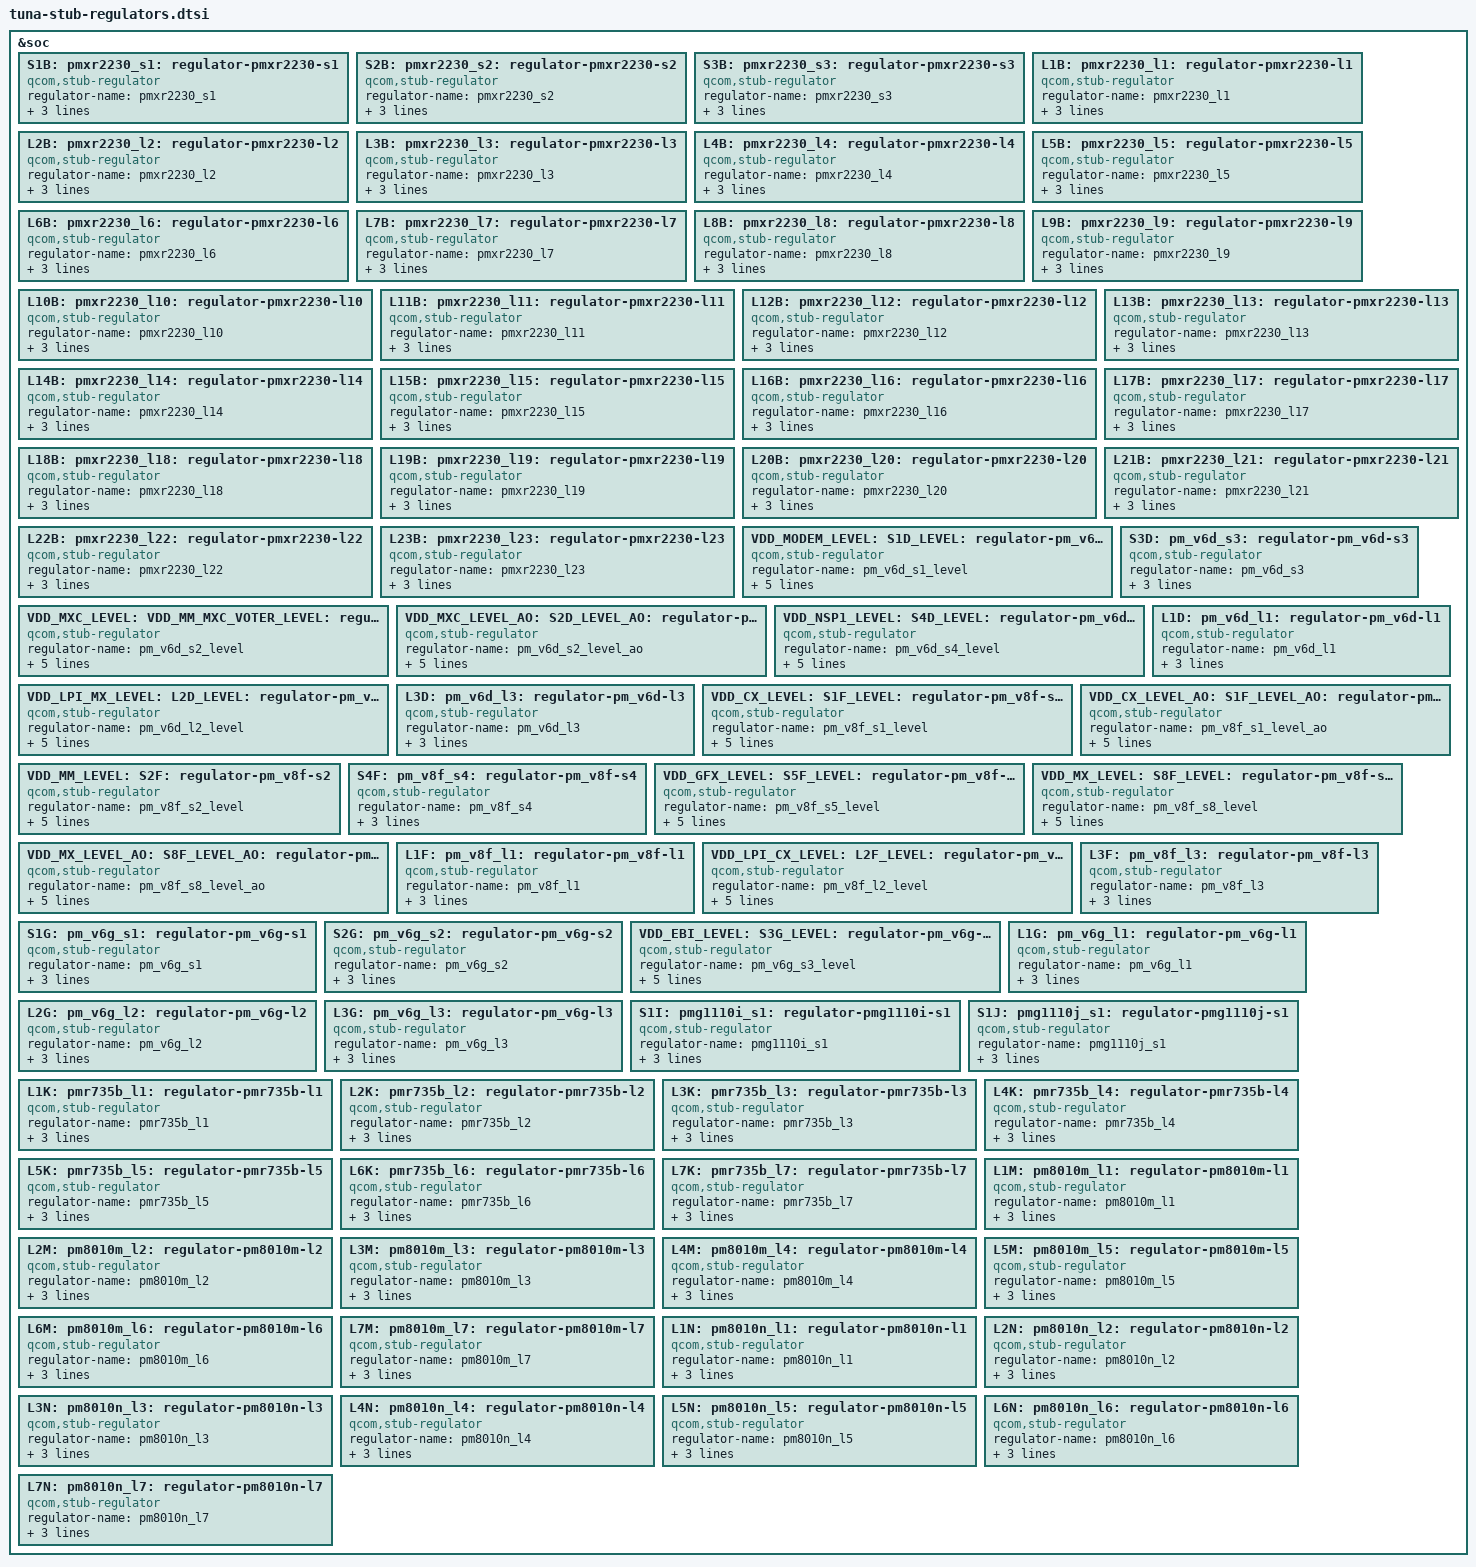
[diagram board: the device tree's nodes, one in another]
// SPDX-License-Identifier: BSD-3-Clause
/*
 * Copyright (c) 2023-2024 Qualcomm Innovation Center, Inc. All rights reserved.
 */

#include <dt-bindings/regulator/qcom,rpmh-regulator-levels.h>

&soc {

		S1B:
		pmxr2230_s1: regulator-pmxr2230-s1 {
			compatible = "qcom,stub-regulator";
			regulator-name = "pmxr2230_s1";
			qcom,hpm-min-load = <10000>;
			regulator-min-microvolt = <1850000>;
			regulator-max-microvolt = <2100000>;
		};

		S2B:
		pmxr2230_s2: regulator-pmxr2230-s2 {
			compatible = "qcom,stub-regulator";
			regulator-name = "pmxr2230_s2";
			qcom,hpm-min-load = <10000>;
			regulator-min-microvolt = <1250000>;
			regulator-max-microvolt = <2100000>;
		};

		S3B:
		pmxr2230_s3: regulator-pmxr2230-s3 {
			compatible = "qcom,stub-regulator";
			regulator-name = "pmxr2230_s3";
			qcom,hpm-min-load = <10000>;
			regulator-min-microvolt = <690000>;
			regulator-max-microvolt = <2100000>;
		};

		L1B:
		pmxr2230_l1: regulator-pmxr2230-l1 {
			compatible = "qcom,stub-regulator";
			regulator-name = "pmxr2230_l1";
			qcom,hpm-min-load = <10000>;
			regulator-min-microvolt = <866000>;
			regulator-max-microvolt = <958000>;
		};

		L2B:
		pmxr2230_l2: regulator-pmxr2230-l2 {
			compatible = "qcom,stub-regulator";
			regulator-name = "pmxr2230_l2";
			qcom,hpm-min-load = <10000>;
			regulator-min-microvolt = <720000>;
			regulator-max-microvolt = <950000>;
		};

		L3B:
		pmxr2230_l3: regulator-pmxr2230-l3 {
			compatible = "qcom,stub-regulator";
			regulator-name = "pmxr2230_l3";
			qcom,hpm-min-load = <10000>;
			regulator-min-microvolt = <831000>;
			regulator-max-microvolt = <919000>;
		};

		L4B:
		pmxr2230_l4: regulator-pmxr2230-l4 {
			compatible = "qcom,stub-regulator";
			regulator-name = "pmxr2230_l4";
			qcom,hpm-min-load = <10000>;
			regulator-min-microvolt = <1080000>;
			regulator-max-microvolt = <1320000>;
		};

		L5B:
		pmxr2230_l5: regulator-pmxr2230-l5 {
			compatible = "qcom,stub-regulator";
			regulator-name = "pmxr2230_l5";
			qcom,hpm-min-load = <10000>;
			regulator-min-microvolt = <1000000>;
			regulator-max-microvolt = <1980000>;
		};

		L6B:
		pmxr2230_l6: regulator-pmxr2230-l6 {
			compatible = "qcom,stub-regulator";
			regulator-name = "pmxr2230_l6";
			qcom,hpm-min-load = <10000>;
			regulator-min-microvolt = <1170000>;
			regulator-max-microvolt = <1370000>;
		};

		L7B:
		pmxr2230_l7: regulator-pmxr2230-l7 {
			compatible = "qcom,stub-regulator";
			regulator-name = "pmxr2230_l7";
			qcom,hpm-min-load = <10000>;
			regulator-min-microvolt = <1080000>;
			regulator-max-microvolt = <1980000>;
		};

		L8B:
		pmxr2230_l8: regulator-pmxr2230-l8 {
			compatible = "qcom,stub-regulator";
			regulator-name = "pmxr2230_l8";
			qcom,hpm-min-load = <10000>;
			regulator-min-microvolt = <1650000>;
			regulator-max-microvolt = <1950000>;
		};

		L9B:
		pmxr2230_l9: regulator-pmxr2230-l9 {
			compatible = "qcom,stub-regulator";
			regulator-name = "pmxr2230_l9";
			qcom,hpm-min-load = <10000>;
			regulator-min-microvolt = <756000>;
			regulator-max-microvolt = <816000>;
		};

		L10B:
		pmxr2230_l10: regulator-pmxr2230-l10 {
			compatible = "qcom,stub-regulator";
			regulator-name = "pmxr2230_l10";
			qcom,hpm-min-load = <10000>;
			regulator-min-microvolt = <866000>;
			regulator-max-microvolt = <931000>;
		};

		L11B:
		pmxr2230_l11: regulator-pmxr2230-l11 {
			compatible = "qcom,stub-regulator";
			regulator-name = "pmxr2230_l11";
			qcom,hpm-min-load = <10000>;
			regulator-min-microvolt = <1620000>;
			regulator-max-microvolt = <2000000>;
		};

		L12B:
		pmxr2230_l12: regulator-pmxr2230-l12 {
			compatible = "qcom,stub-regulator";
			regulator-name = "pmxr2230_l12";
			qcom,hpm-min-load = <10000>;
			regulator-min-microvolt = <2400000>;
			regulator-max-microvolt = <3300000>;
		};

		L13B:
		pmxr2230_l13: regulator-pmxr2230-l13 {
			compatible = "qcom,stub-regulator";
			regulator-name = "pmxr2230_l13";
			qcom,hpm-min-load = <10000>;
			regulator-min-microvolt = <2700000>;
			regulator-max-microvolt = <3300000>;
		};

		L14B:
		pmxr2230_l14: regulator-pmxr2230-l14 {
			compatible = "qcom,stub-regulator";
			regulator-name = "pmxr2230_l14";
			qcom,hpm-min-load = <10000>;
			regulator-min-microvolt = <1504000>;
			regulator-max-microvolt = <3544000>;
		};

		L15B:
		pmxr2230_l15: regulator-pmxr2230-l15 {
			compatible = "qcom,stub-regulator";
			regulator-name = "pmxr2230_l15";
			qcom,hpm-min-load = <10000>;
			regulator-min-microvolt = <1620000>;
			regulator-max-microvolt = <3300000>;
		};

		L16B:
		pmxr2230_l16: regulator-pmxr2230-l16 {
			compatible = "qcom,stub-regulator";
			regulator-name = "pmxr2230_l16";
			qcom,hpm-min-load = <10000>;
			regulator-min-microvolt = <2900000>;
			regulator-max-microvolt = <3544000>;
		};

		L17B:
		pmxr2230_l17: regulator-pmxr2230-l17 {
			compatible = "qcom,stub-regulator";
			regulator-name = "pmxr2230_l17";
			qcom,hpm-min-load = <10000>;
			regulator-min-microvolt = <2700000>;
			regulator-max-microvolt = <3544000>;
		};

		L18B:
		pmxr2230_l18: regulator-pmxr2230-l18 {
			compatible = "qcom,stub-regulator";
			regulator-name = "pmxr2230_l18";
			qcom,hpm-min-load = <10000>;
			regulator-min-microvolt = <1600000>;
			regulator-max-microvolt = <3544000>;
		};

		L19B:
		pmxr2230_l19: regulator-pmxr2230-l19 {
			compatible = "qcom,stub-regulator";
			regulator-name = "pmxr2230_l19";
			qcom,hpm-min-load = <10000>;
			regulator-min-microvolt = <2600000>;
			regulator-max-microvolt = <3544000>;
		};

		L20B:
		pmxr2230_l20: regulator-pmxr2230-l20 {
			compatible = "qcom,stub-regulator";
			regulator-name = "pmxr2230_l20";
			qcom,hpm-min-load = <10000>;
			regulator-min-microvolt = <1504000>;
			regulator-max-microvolt = <3544000>;
		};

		L21B:
		pmxr2230_l21: regulator-pmxr2230-l21 {
			compatible = "qcom,stub-regulator";
			regulator-name = "pmxr2230_l21";
			qcom,hpm-min-load = <10000>;
			regulator-min-microvolt = <1504000>;
			regulator-max-microvolt = <3544000>;
		};

		L22B:
		pmxr2230_l22: regulator-pmxr2230-l22 {
			compatible = "qcom,stub-regulator";
			regulator-name = "pmxr2230_l22";
			qcom,hpm-min-load = <10000>;
			regulator-min-microvolt = <2700000>;
			regulator-max-microvolt = <3400000>;
		};

		L23B:
		pmxr2230_l23: regulator-pmxr2230-l23 {
			compatible = "qcom,stub-regulator";
			regulator-name = "pmxr2230_l23";
			qcom,hpm-min-load = <10000>;
			regulator-min-microvolt = <1650000>;
			regulator-max-microvolt = <3544000>;
		};

		VDD_MODEM_LEVEL:
		S1D_LEVEL:
		pm_v6d_s1_level: regulator-pm_v6d-s1-level {
			compatible = "qcom,stub-regulator";
			regulator-name = "pm_v6d_s1_level";
			qcom,hpm-min-load = <10000>;
			regulator-min-microvolt =
				<RPMH_REGULATOR_LEVEL_RETENTION>;
			regulator-max-microvolt = <RPMH_REGULATOR_LEVEL_MAX>;
		};

		VDD_MXC_LEVEL:
		VDD_MM_MXC_VOTER_LEVEL:
		VDD_GFX_MXC_VOTER_LEVEL:
		S2D_LEVEL:
		pm_v6d_s2_level: regulator-pm_v6d-s2-level {
			compatible = "qcom,stub-regulator";
			regulator-name = "pm_v6d_s2_level";
			qcom,hpm-min-load = <10000>;
			regulator-min-microvolt =
				<RPMH_REGULATOR_LEVEL_RETENTION>;
			regulator-max-microvolt = <RPMH_REGULATOR_LEVEL_MAX>;
		};

		VDD_MXC_LEVEL_AO:
		S2D_LEVEL_AO:
		pm_v6d_s2_level_ao: regulator-pm_v6d-s2-level-ao {
			compatible = "qcom,stub-regulator";
			regulator-name = "pm_v6d_s2_level_ao";
			qcom,hpm-min-load = <10000>;
			regulator-min-microvolt =
				<RPMH_REGULATOR_LEVEL_RETENTION>;
			regulator-max-microvolt = <RPMH_REGULATOR_LEVEL_MAX>;
		};

		S3D:
		pm_v6d_s3: regulator-pm_v6d-s3 {
			compatible = "qcom,stub-regulator";
			regulator-name = "pm_v6d_s3";
			qcom,hpm-min-load = <10000>;
			regulator-min-microvolt = <870000>;
			regulator-max-microvolt = <970000>;
		};

		VDD_NSP1_LEVEL:
		S4D_LEVEL:
		pm_v6d_s4_level: regulator-pm_v6d-s4-level {
			compatible = "qcom,stub-regulator";
			regulator-name = "pm_v6d_s4_level";
			qcom,hpm-min-load = <10000>;
			regulator-min-microvolt =
				<RPMH_REGULATOR_LEVEL_RETENTION>;
			regulator-max-microvolt = <RPMH_REGULATOR_LEVEL_MAX>;
		};

		L1D:
		pm_v6d_l1: regulator-pm_v6d-l1 {
			compatible = "qcom,stub-regulator";
			regulator-name = "pm_v6d_l1";
			qcom,hpm-min-load = <10000>;
			regulator-min-microvolt = <320000>;
			regulator-max-microvolt = <2000000>;
		};

		VDD_LPI_MX_LEVEL:
		L2D_LEVEL:
		pm_v6d_l2_level: regulator-pm_v6d-l2-level {
			compatible = "qcom,stub-regulator";
			regulator-name = "pm_v6d_l2_level";
			qcom,hpm-min-load = <10000>;
			regulator-min-microvolt =
				<RPMH_REGULATOR_LEVEL_RETENTION>;
			regulator-max-microvolt = <RPMH_REGULATOR_LEVEL_MAX>;
		};

		L3D:
		pm_v6d_l3: regulator-pm_v6d-l3 {
			compatible = "qcom,stub-regulator";
			regulator-name = "pm_v6d_l3";
			qcom,hpm-min-load = <10000>;
			regulator-min-microvolt = <1030000>;
			regulator-max-microvolt = <1350000>;
		};

		VDD_CX_LEVEL:
		S1F_LEVEL:
		pm_v8f_s1_level: regulator-pm_v8f-s1-level {
			compatible = "qcom,stub-regulator";
			regulator-name = "pm_v8f_s1_level";
			qcom,hpm-min-load = <10000>;
			regulator-min-microvolt =
				<RPMH_REGULATOR_LEVEL_RETENTION>;
			regulator-max-microvolt = <RPMH_REGULATOR_LEVEL_MAX>;
		};

		VDD_CX_LEVEL_AO:
		S1F_LEVEL_AO:
		pm_v8f_s1_level_ao: regulator-pm_v8f-s1-level-ao {
			compatible = "qcom,stub-regulator";
			regulator-name = "pm_v8f_s1_level_ao";
			qcom,hpm-min-load = <10000>;
			regulator-min-microvolt =
				<RPMH_REGULATOR_LEVEL_RETENTION>;
			regulator-max-microvolt = <RPMH_REGULATOR_LEVEL_MAX>;
		};

		VDD_MM_LEVEL:
		S2F:
		pm_v8f_s2: regulator-pm_v8f-s2 {
			compatible = "qcom,stub-regulator";
			regulator-name = "pm_v8f_s2_level";
			qcom,hpm-min-load = <10000>;
			regulator-min-microvolt =
				<RPMH_REGULATOR_LEVEL_RETENTION>;
			regulator-max-microvolt = <RPMH_REGULATOR_LEVEL_MAX>;
		};

		S4F:
		pm_v8f_s4: regulator-pm_v8f-s4 {
			compatible = "qcom,stub-regulator";
			regulator-name = "pm_v8f_s4";
			qcom,hpm-min-load = <10000>;
			regulator-min-microvolt = <300000>;
			regulator-max-microvolt = <570000>;
		};

		VDD_GFX_LEVEL:
		S5F_LEVEL:
		pm_v8f_s5_level: regulator-pm_v8f-s5-level {
			compatible = "qcom,stub-regulator";
			regulator-name = "pm_v8f_s5_level";
			qcom,hpm-min-load = <10000>;
			regulator-min-microvolt =
				<RPMH_REGULATOR_LEVEL_RETENTION>;
			regulator-max-microvolt = <RPMH_REGULATOR_LEVEL_MAX>;
		};

		VDD_MX_LEVEL:
		S8F_LEVEL:
		pm_v8f_s8_level: regulator-pm_v8f-s8-level {
			compatible = "qcom,stub-regulator";
			regulator-name = "pm_v8f_s8_level";
			qcom,hpm-min-load = <10000>;
			regulator-min-microvolt =
				<RPMH_REGULATOR_LEVEL_RETENTION>;
			regulator-max-microvolt = <RPMH_REGULATOR_LEVEL_MAX>;
		};

		VDD_MX_LEVEL_AO:
		S8F_LEVEL_AO:
		pm_v8f_s8_level_ao: regulator-pm_v8f-s8-level-ao {
			compatible = "qcom,stub-regulator";
			regulator-name = "pm_v8f_s8_level_ao";
			qcom,hpm-min-load = <10000>;
			regulator-min-microvolt =
				<RPMH_REGULATOR_LEVEL_RETENTION>;
			regulator-max-microvolt = <RPMH_REGULATOR_LEVEL_MAX>;
		};

		L1F:
		pm_v8f_l1: regulator-pm_v8f-l1 {
			compatible = "qcom,stub-regulator";
			regulator-name = "pm_v8f_l1";
			qcom,hpm-min-load = <10000>;
			regulator-min-microvolt = <866000>;
			regulator-max-microvolt = <958000>;
		};

		VDD_LPI_CX_LEVEL:
		L2F_LEVEL:
		pm_v8f_l2_level: regulator-pm_v8f-l2-level {
			compatible = "qcom,stub-regulator";
			regulator-name = "pm_v8f_l2_level";
			qcom,hpm-min-load = <10000>;
			regulator-min-microvolt =
				<RPMH_REGULATOR_LEVEL_RETENTION>;
			regulator-max-microvolt = <RPMH_REGULATOR_LEVEL_MAX>;
		};

		L3F:
		pm_v8f_l3: regulator-pm_v8f-l3 {
			compatible = "qcom,stub-regulator";
			regulator-name = "pm_v8f_l3";
			qcom,hpm-min-load = <10000>;
			regulator-min-microvolt = <1140000>;
			regulator-max-microvolt = <1260000>;
		};

		S1G:
		pm_v6g_s1: regulator-pm_v6g-s1 {
			compatible = "qcom,stub-regulator";
			regulator-name = "pm_v6g_s1";
			qcom,hpm-min-load = <10000>;
			regulator-min-microvolt = <2156000>;
			regulator-max-microvolt = <2400000>;
		};

		S2G:
		pm_v6g_s2: regulator-pm_v6g-s2 {
			compatible = "qcom,stub-regulator";
			regulator-name = "pm_v6g_s2";
			qcom,hpm-min-load = <10000>;
			regulator-min-microvolt = <1010000>;
			regulator-max-microvolt = <1170000>;
		};

		VDD_EBI_LEVEL:
		S3G_LEVEL:
		pm_v6g_s3_level: regulator-pm_v6g-s3-level {
			compatible = "qcom,stub-regulator";
			regulator-name = "pm_v6g_s3_level";
			qcom,hpm-min-load = <10000>;
			regulator-min-microvolt =
				<RPMH_REGULATOR_LEVEL_RETENTION>;
			regulator-max-microvolt = <RPMH_REGULATOR_LEVEL_MAX>;
		};

		L1G:
		pm_v6g_l1: regulator-pm_v6g-l1 {
			compatible = "qcom,stub-regulator";
			regulator-name = "pm_v6g_l1";
			qcom,hpm-min-load = <10000>;
			regulator-min-microvolt = <1600000>;
			regulator-max-microvolt = <2000000>;
		};

		L2G:
		pm_v6g_l2: regulator-pm_v6g-l2 {
			compatible = "qcom,stub-regulator";
			regulator-name = "pm_v6g_l2";
			qcom,hpm-min-load = <10000>;
			regulator-min-microvolt = <700000>;
			regulator-max-microvolt = <2000000>;
		};

		L3G:
		pm_v6g_l3: regulator-pm_v6g-l3 {
			compatible = "qcom,stub-regulator";
			regulator-name = "pm_v6g_l3";
			qcom,hpm-min-load = <10000>;
			regulator-min-microvolt = <1620000>;
			regulator-max-microvolt = <1980000>;
		};

		S1I:
		pmg1110i_s1: regulator-pmg1110i-s1 {
			compatible = "qcom,stub-regulator";
			regulator-name = "pmg1110i_s1";
			qcom,hpm-min-load = <10000>;
			regulator-min-microvolt = <320000>;
			regulator-max-microvolt = <1352000>;
		};

		S1J:
		pmg1110j_s1: regulator-pmg1110j-s1 {
			compatible = "qcom,stub-regulator";
			regulator-name = "pmg1110j_s1";
			qcom,hpm-min-load = <10000>;
			regulator-min-microvolt = <504000>;
			regulator-max-microvolt = <868000>;
		};

		L1K:
		pmr735b_l1: regulator-pmr735b-l1 {
			compatible = "qcom,stub-regulator";
			regulator-name = "pmr735b_l1";
			qcom,hpm-min-load = <10000>;
			regulator-min-microvolt = <488000>;
			regulator-max-microvolt = <912000>;
		};

		L2K:
		pmr735b_l2: regulator-pmr735b-l2 {
			compatible = "qcom,stub-regulator";
			regulator-name = "pmr735b_l2";
			qcom,hpm-min-load = <10000>;
			regulator-min-microvolt = <920000>;
			regulator-max-microvolt = <969000>;
		};

		L3K:
		pmr735b_l3: regulator-pmr735b-l3 {
			compatible = "qcom,stub-regulator";
			regulator-name = "pmr735b_l3";
			qcom,hpm-min-load = <10000>;
			regulator-min-microvolt = <1080000>;
			regulator-max-microvolt = <1350000>;
		};

		L4K:
		pmr735b_l4: regulator-pmr735b-l4 {
			compatible = "qcom,stub-regulator";
			regulator-name = "pmr735b_l4";
			qcom,hpm-min-load = <10000>;
			regulator-min-microvolt = <1100000>;
			regulator-max-microvolt = <1950000>;
		};

		L5K:
		pmr735b_l5: regulator-pmr735b-l5 {
			compatible = "qcom,stub-regulator";
			regulator-name = "pmr735b_l5";
			qcom,hpm-min-load = <10000>;
			regulator-min-microvolt = <504000>;
			regulator-max-microvolt = <868000>;
		};

		L6K:
		pmr735b_l6: regulator-pmr735b-l6 {
			compatible = "qcom,stub-regulator";
			regulator-name = "pmr735b_l6";
			qcom,hpm-min-load = <10000>;
			regulator-min-microvolt = <1500000>;
			regulator-max-microvolt = <2000000>;
		};

		L7K:
		pmr735b_l7: regulator-pmr735b-l7 {
			compatible = "qcom,stub-regulator";
			regulator-name = "pmr735b_l7";
			qcom,hpm-min-load = <10000>;
			regulator-min-microvolt = <504000>;
			regulator-max-microvolt = <868000>;
		};

		L1M:
		pm8010m_l1: regulator-pm8010m-l1 {
			compatible = "qcom,stub-regulator";
			regulator-name = "pm8010m_l1";
			qcom,hpm-min-load = <10000>;
			regulator-min-microvolt = <1000000>;
			regulator-max-microvolt = <1200000>;
		};

		L2M:
		pm8010m_l2: regulator-pm8010m-l2 {
			compatible = "qcom,stub-regulator";
			regulator-name = "pm8010m_l2";
			qcom,hpm-min-load = <10000>;
			regulator-min-microvolt = <950000>;
			regulator-max-microvolt = <1150000>;
		};

		L3M:
		pm8010m_l3: regulator-pm8010m-l3 {
			compatible = "qcom,stub-regulator";
			regulator-name = "pm8010m_l3";
			qcom,hpm-min-load = <10000>;
			regulator-min-microvolt = <2700000>;
			regulator-max-microvolt = <2900000>;
		};

		L4M:
		pm8010m_l4: regulator-pm8010m-l4 {
			compatible = "qcom,stub-regulator";
			regulator-name = "pm8010m_l4";
			qcom,hpm-min-load = <10000>;
			regulator-min-microvolt = <2700000>;
			regulator-max-microvolt = <2900000>;
		};

		L5M:
		pm8010m_l5: regulator-pm8010m-l5 {
			compatible = "qcom,stub-regulator";
			regulator-name = "pm8010m_l5";
			qcom,hpm-min-load = <10000>;
			regulator-min-microvolt = <1504000>;
			regulator-max-microvolt = <1980000>;
		};

		L6M:
		pm8010m_l6: regulator-pm8010m-l6 {
			compatible = "qcom,stub-regulator";
			regulator-name = "pm8010m_l6";
			qcom,hpm-min-load = <10000>;
			regulator-min-microvolt = <2700000>;
			regulator-max-microvolt = <2900000>;
		};

		L7M:
		pm8010m_l7: regulator-pm8010m-l7 {
			compatible = "qcom,stub-regulator";
			regulator-name = "pm8010m_l7";
			qcom,hpm-min-load = <10000>;
			regulator-min-microvolt = <2700000>;
			regulator-max-microvolt = <3000000>;
		};

		L1N:
		pm8010n_l1: regulator-pm8010n-l1 {
			compatible = "qcom,stub-regulator";
			regulator-name = "pm8010n_l1";
			qcom,hpm-min-load = <10000>;
			regulator-min-microvolt = <1050000>;
			regulator-max-microvolt = <1200000>;
		};

		L2N:
		pm8010n_l2: regulator-pm8010n-l2 {
			compatible = "qcom,stub-regulator";
			regulator-name = "pm8010n_l2";
			qcom,hpm-min-load = <10000>;
			regulator-min-microvolt = <1050000>;
			regulator-max-microvolt = <1150000>;
		};

		L3N:
		pm8010n_l3: regulator-pm8010n-l3 {
			compatible = "qcom,stub-regulator";
			regulator-name = "pm8010n_l3";
			qcom,hpm-min-load = <10000>;
			regulator-min-microvolt = <1792000>;
			regulator-max-microvolt = <1900000>;
		};

		L4N:
		pm8010n_l4: regulator-pm8010n-l4 {
			compatible = "qcom,stub-regulator";
			regulator-name = "pm8010n_l4";
			qcom,hpm-min-load = <10000>;
			regulator-min-microvolt = <1792000>;
			regulator-max-microvolt = <3312000>;
		};

		L5N:
		pm8010n_l5: regulator-pm8010n-l5 {
			compatible = "qcom,stub-regulator";
			regulator-name = "pm8010n_l5";
			qcom,hpm-min-load = <10000>;
			regulator-min-microvolt = <1300000>;
			regulator-max-microvolt = <1300000>;
		};

		L6N:
		pm8010n_l6: regulator-pm8010n-l6 {
			compatible = "qcom,stub-regulator";
			regulator-name = "pm8010n_l6";
			qcom,hpm-min-load = <10000>;
			regulator-min-microvolt = <2700000>;
			regulator-max-microvolt = <2900000>;
		};

		L7N:
		pm8010n_l7: regulator-pm8010n-l7 {
			compatible = "qcom,stub-regulator";
			regulator-name = "pm8010n_l7";
			qcom,hpm-min-load = <10000>;
			regulator-min-microvolt = <3130000>;
			regulator-max-microvolt = <3470000>;
		};
};
